VERSION ""

NS_ :

BS_:

BU_: BMU DTI_L DTI_R ECU SBG SHDN C125

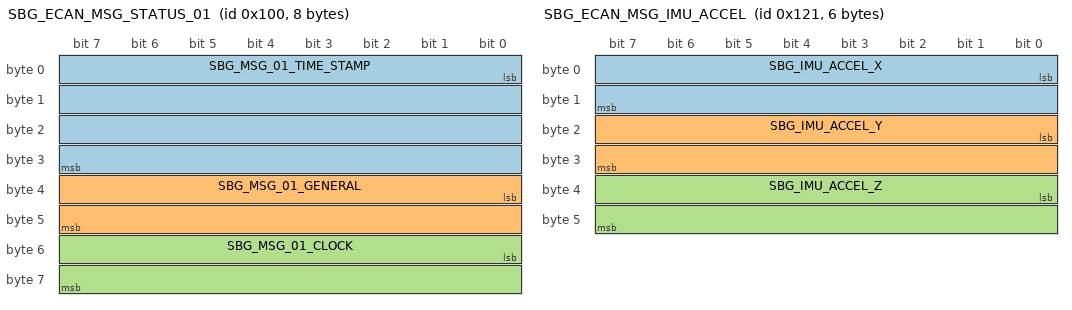
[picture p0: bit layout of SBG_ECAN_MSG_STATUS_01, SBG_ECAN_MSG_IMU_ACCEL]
BO_ 256 SBG_ECAN_MSG_STATUS_01: 8 SBG
 SG_ SBG_MSG_01_TIME_STAMP : 0|32@1+ (1,0) [0|4294970000] "µs" C125
 SG_ SBG_MSG_01_GENERAL : 32|16@1+ (1,0) [0|65535] "" C125
 SG_ SBG_MSG_01_CLOCK : 48|16@1+ (1,0) [0|65535] "" C125

BO_ 289 SBG_ECAN_MSG_IMU_ACCEL: 6 SBG
 SG_ SBG_IMU_ACCEL_X : 0|16@1- (0.01,0) [-327.68|327.67] "m.s-2" C125
 SG_ SBG_IMU_ACCEL_Y : 16|16@1- (0.01,0) [-327.68|327.67] "m.s-2" C125
 SG_ SBG_IMU_ACCEL_Z : 32|16@1- (0.01,0) [-327.68|327.67] "m.s-2" C125

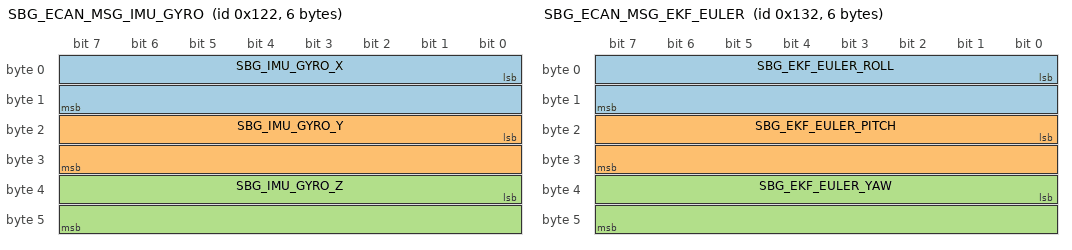
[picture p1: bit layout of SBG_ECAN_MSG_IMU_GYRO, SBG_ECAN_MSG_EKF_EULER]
BO_ 290 SBG_ECAN_MSG_IMU_GYRO: 6 SBG
 SG_ SBG_IMU_GYRO_X : 0|16@1- (0.001,0) [-32.768|32.767] "rad.s-1" C125
 SG_ SBG_IMU_GYRO_Y : 16|16@1- (0.001,0) [-32.768|32.767] "rad.s-1" C125
 SG_ SBG_IMU_GYRO_Z : 32|16@1- (0.001,0) [-32.768|32.767] "rad.s-1" C125

BO_ 304 SBG_ECAN_MSG_EKF_INFO: 4 SBG
 SG_ SBG_EFK_TIME_STAMP : 0|32@1+ (1,0) [0|4294970000] "µs" C125

BO_ 306 SBG_ECAN_MSG_EKF_EULER: 6 SBG
 SG_ SBG_EKF_EULER_ROLL : 0|16@1- (0.0001,0) [-3.2768|3.2767] "rad" C125
 SG_ SBG_EKF_EULER_PITCH : 16|16@1- (0.0001,0) [-3.2768|3.2767] "rad" C125
 SG_ SBG_EKF_EULER_YAW : 32|16@1- (0.0001,0) [-3.2768|3.2767] "rad" C125

BO_ 308 SBG_ECAN_MSG_EKF_POS: 8 SBG
 SG_ SBG_EKF_POS_LATITUDE : 0|32@1- (0.0000001,0) [-214.7483648|214.7483647] "°" C125
 SG_ SBG_EKF_POS_LONGITUDE : 32|32@1- (0.0000001,0) [-214.7483648|214.7483647] "°" C125

BO_ 309 SBG_ECAN_MSG_EKF_ALTITUDE: 6 SBG
 SG_ SBG_EKF_ALTITUDE : 0|32@1- (0.001,0) [-2147480|2147480] "m" C125
 SG_ SBG_EKF_UNDULATION : 32|16@1- (0.005,0) [-163.84|163.835] "m" C125

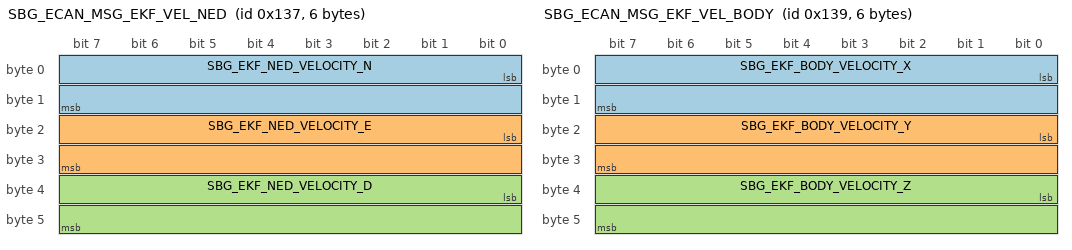
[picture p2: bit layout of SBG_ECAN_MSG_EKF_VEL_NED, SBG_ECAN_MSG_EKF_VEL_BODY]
BO_ 311 SBG_ECAN_MSG_EKF_VEL_NED: 6 SBG
 SG_ SBG_EKF_NED_VELOCITY_N : 0|16@1- (0.01,0) [-327.68|327.67] "m.s-1" C125
 SG_ SBG_EKF_NED_VELOCITY_E : 16|16@1- (0.01,0) [-327.68|327.67] "m.s-1" C125
 SG_ SBG_EKF_NED_VELOCITY_D : 32|16@1- (0.01,0) [-327.68|327.67] "m.s-1" C125

BO_ 313 SBG_ECAN_MSG_EKF_VEL_BODY: 6 SBG
 SG_ SBG_EKF_BODY_VELOCITY_X : 0|16@1- (0.01,0) [-327.68|327.67] "m.s-1" C125
 SG_ SBG_EKF_BODY_VELOCITY_Y : 16|16@1- (0.01,0) [-327.68|327.67] "m.s-1" C125
 SG_ SBG_EKF_BODY_VELOCITY_Z : 32|16@1- (0.01,0) [-327.68|327.67] "m.s-1" C125

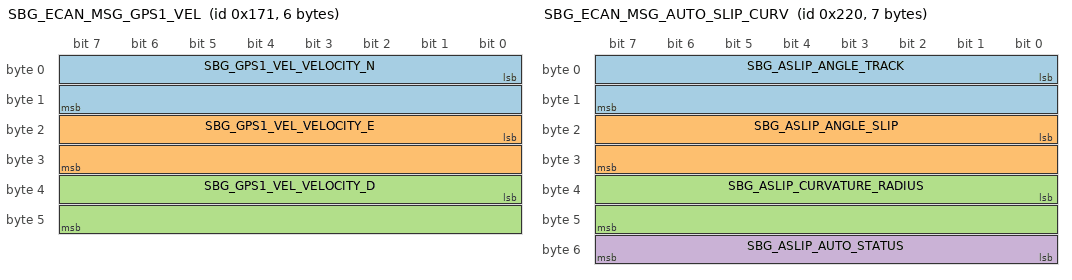
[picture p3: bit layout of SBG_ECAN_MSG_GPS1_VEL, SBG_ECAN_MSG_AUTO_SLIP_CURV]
BO_ 369 SBG_ECAN_MSG_GPS1_VEL: 6 SBG
 SG_ SBG_GPS1_VEL_VELOCITY_N : 0|16@1- (0.01,0) [-327.68|327.67] "m.s-1" C125
 SG_ SBG_GPS1_VEL_VELOCITY_E : 16|16@1- (0.01,0) [-327.68|327.67] "m.s-1" C125
 SG_ SBG_GPS1_VEL_VELOCITY_D : 32|16@1- (0.01,0) [-327.68|327.67] "m.s-1" C125

BO_ 373 SBG_ECAN_MSG_GPS1_POS: 8 SBG
 SG_ SBG_GPS1_POS_LATITUDE : 0|32@1- (0.0000001,0) [-214.7483648|214.7483647] "°" C125
 SG_ SBG_GPS1_POS_LONGITUDE : 32|32@1- (0.0000001,0) [-214.7483648|214.7483647] "°" C125

BO_ 544 SBG_ECAN_MSG_AUTO_SLIP_CURV: 7 SBG
 SG_ SBG_ASLIP_ANGLE_TRACK : 0|16@1- (0.0001,0) [-3.2768|3.2767] "rad" C125
 SG_ SBG_ASLIP_ANGLE_SLIP : 16|16@1- (0.0001,0) [-3.2768|3.2767] "rad" C125
 SG_ SBG_ASLIP_CURVATURE_RADIUS : 32|16@1+ (0.01,0) [0|655.35] "m" C125
 SG_ SBG_ASLIP_AUTO_STATUS : 48|8@1+ (1,0) [0|255] "" C125

BO_ 2147484988 DTI_L_SET_REL_CURRENT: 8 ECU
 SG_ DTI_L_CmdRelCurrent : 7|16@0- (0.1,0) [-100|100] "%" C125

BO_ 2147484989 DTI_R_SET_REL_CURRENT: 8 ECU
 SG_ DTI_R_CmdRelCurrent : 7|16@0- (0.1,0) [-100|100] "%" C125

BO_ 2147486780 DTI_L_DRIVE_ENABLE: 8 ECU
 SG_ DTI_L_CmdDriveEnable : 7|8@0+ (1,0) [0|255] "" C125

BO_ 2147486781 DTI_R_DRIVE_ENABLE: 8 ECU
 SG_ DTI_R_CmdDriveEnable : 7|8@0+ (1,0) [0|255] "" C125

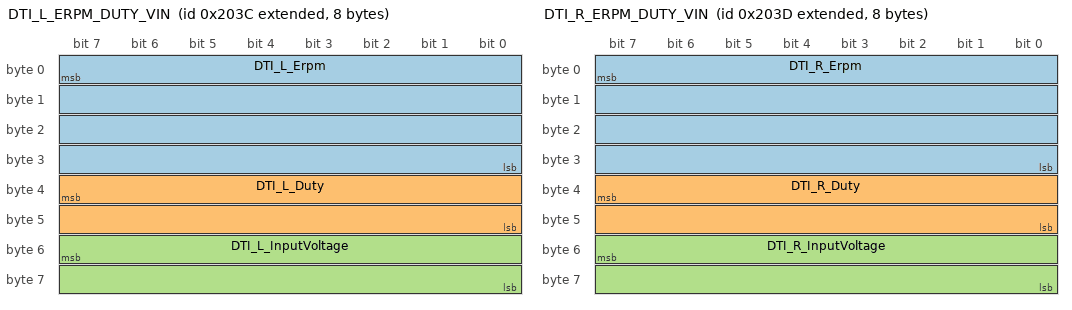
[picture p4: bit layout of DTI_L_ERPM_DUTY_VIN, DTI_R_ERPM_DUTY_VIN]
BO_ 2147491900 DTI_L_ERPM_DUTY_VIN: 8 DTI_L
 SG_ DTI_L_Erpm : 7|32@0- (1,0) [-2147483648|2147483647] "rpm" C125
 SG_ DTI_L_Duty : 39|16@0- (0.1,0) [-3276.8|3276.7] "%" C125
 SG_ DTI_L_InputVoltage : 55|16@0- (1,0) [-32768|32767] "V" C125

BO_ 2147491901 DTI_R_ERPM_DUTY_VIN: 8 DTI_R
 SG_ DTI_R_Erpm : 7|32@0- (1,0) [-2147483648|2147483647] "rpm" C125
 SG_ DTI_R_Duty : 39|16@0- (0.1,0) [-3276.8|3276.7] "%" C125
 SG_ DTI_R_InputVoltage : 55|16@0- (1,0) [-32768|32767] "V" C125

BO_ 2147492156 DTI_L_CURRENTS: 8 DTI_L
 SG_ DTI_L_AcCurrent : 7|16@0- (0.1,0) [-3276.8|3276.7] "A" C125
 SG_ DTI_L_DcCurrent : 23|16@0- (0.1,0) [-3276.8|3276.7] "A" C125

BO_ 2147492157 DTI_R_CURRENTS: 8 DTI_R
 SG_ DTI_R_AcCurrent : 7|16@0- (0.1,0) [-3276.8|3276.7] "A" C125
 SG_ DTI_R_DcCurrent : 23|16@0- (0.1,0) [-3276.8|3276.7] "A" C125

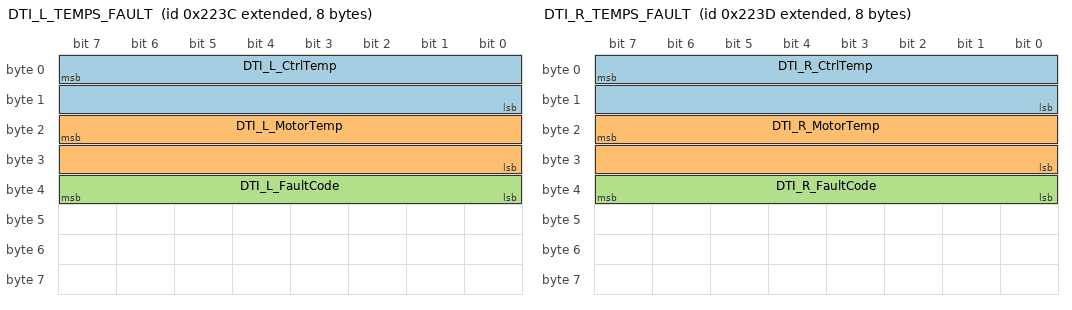
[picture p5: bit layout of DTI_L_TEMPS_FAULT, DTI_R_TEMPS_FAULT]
BO_ 2147492412 DTI_L_TEMPS_FAULT: 8 DTI_L
 SG_ DTI_L_CtrlTemp : 7|16@0- (0.1,0) [-3276.8|3276.7] "degC" C125
 SG_ DTI_L_MotorTemp : 23|16@0- (0.1,0) [-3276.8|3276.7] "degC" C125
 SG_ DTI_L_FaultCode : 39|8@0+ (1,0) [0|255] "" C125

BO_ 2147492413 DTI_R_TEMPS_FAULT: 8 DTI_R
 SG_ DTI_R_CtrlTemp : 7|16@0- (0.1,0) [-3276.8|3276.7] "degC" C125
 SG_ DTI_R_MotorTemp : 23|16@0- (0.1,0) [-3276.8|3276.7] "degC" C125
 SG_ DTI_R_FaultCode : 39|8@0+ (1,0) [0|255] "" C125

BO_ 2147492924 DTI_L_IO_STATUS: 8 DTI_L
 SG_ DTI_L_DriveEnabled : 31|8@0+ (1,0) [0|255] "" C125
 SG_ DTI_L_Limits : 39|16@0+ (1,0) [0|65535] "" C125

BO_ 2147492925 DTI_R_IO_STATUS: 8 DTI_R
 SG_ DTI_R_DriveEnabled : 31|8@0+ (1,0) [0|255] "" C125
 SG_ DTI_R_Limits : 39|16@0+ (1,0) [0|65535] "" C125

BO_ 2281963520 BMU_HEARTBEAT: 8 BMU
 SG_ BMU_State : 0|8@1+ (1,0) [0|255] "" C125
 SG_ BMU_Flags : 8|28@1+ (1,0) [0|268435455] "" C125

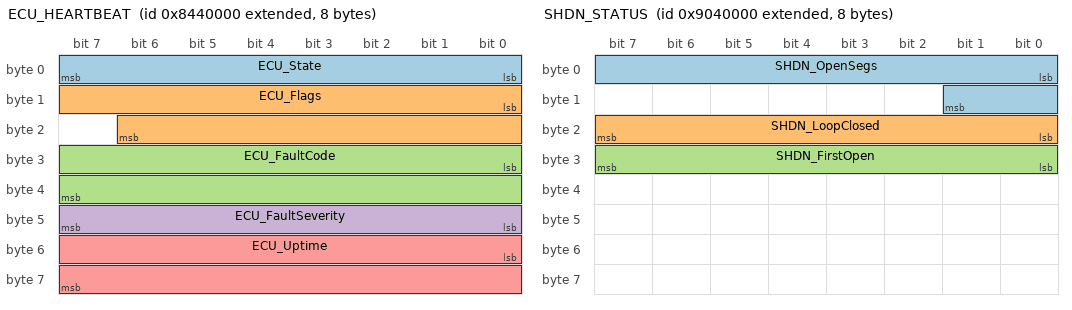
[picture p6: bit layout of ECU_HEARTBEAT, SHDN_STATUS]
BO_ 2286157824 ECU_HEARTBEAT: 8 ECU
 SG_ ECU_State : 0|8@1+ (1,0) [0|255] "" C125
 SG_ ECU_Flags : 8|15@1+ (1,0) [0|32767] "" C125
 SG_ ECU_FaultCode : 24|16@1+ (1,0) [0|65535] "" C125
 SG_ ECU_FaultSeverity : 40|8@1+ (1,0) [0|255] "" C125
 SG_ ECU_Uptime : 48|16@1+ (1,0) [0|65535] "s" C125

BO_ 2298740736 SHDN_STATUS: 8 SHDN
 SG_ SHDN_OpenSegs : 0|10@1+ (1,0) [0|1023] "" C125
 SG_ SHDN_LoopClosed : 16|8@1+ (1,0) [0|255] "" C125
 SG_ SHDN_FirstOpen : 24|8@1+ (1,0) [0|255] "" C125

BO_ 2416446720 BMU_TRANSMIT_PACKINFO: 8 BMU
 SG_ BMU_PackCurrent : 0|32@1- (0.001,0) [-2147483.648|2147483.6469999999] "A" C125
 SG_ BMU_PackVoltage : 32|32@1- (0.001,0) [-2147483.648|2147483.6469999999] "V" C125

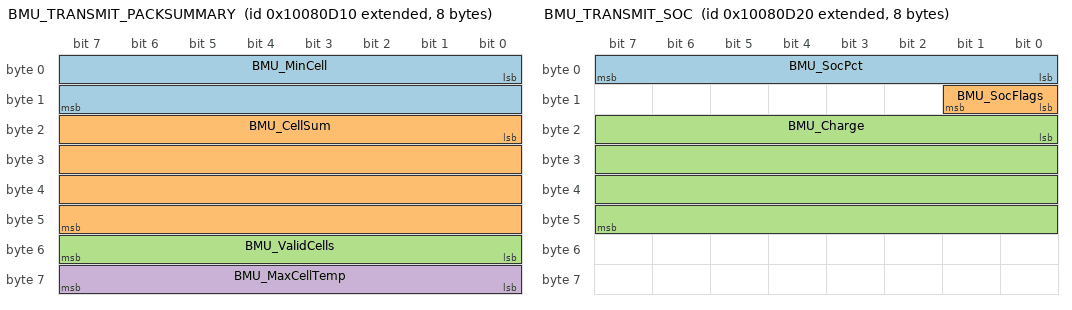
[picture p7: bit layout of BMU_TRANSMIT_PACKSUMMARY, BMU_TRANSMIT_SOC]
BO_ 2416446736 BMU_TRANSMIT_PACKSUMMARY: 8 BMU
 SG_ BMU_MinCell : 0|16@1+ (1,0) [0|65535] "mV" C125
 SG_ BMU_CellSum : 16|32@1+ (1,0) [0|4294967295] "mV" C125
 SG_ BMU_ValidCells : 48|8@1+ (1,0) [0|255] "" C125
 SG_ BMU_MaxCellTemp : 56|8@1+ (1,0) [0|255] "degC" C125

BO_ 2416446752 BMU_TRANSMIT_SOC: 8 BMU
 SG_ BMU_SocPct : 0|8@1+ (1,0) [0|255] "%" C125
 SG_ BMU_SocFlags : 8|2@1+ (1,0) [0|3] "" C125
 SG_ BMU_Charge : 16|32@1- (0.000001,0) [-2147.483648|2147.483647] "Ah" C125

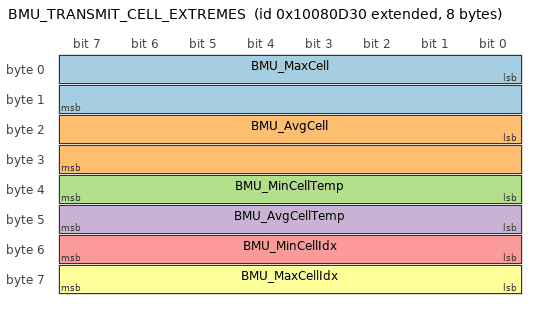
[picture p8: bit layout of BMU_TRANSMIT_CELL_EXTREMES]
BO_ 2416446768 BMU_TRANSMIT_CELL_EXTREMES: 8 BMU
 SG_ BMU_MaxCell : 0|16@1+ (1,0) [0|65535] "mV" C125
 SG_ BMU_AvgCell : 16|16@1+ (1,0) [0|65535] "mV" C125
 SG_ BMU_MinCellTemp : 32|8@1+ (1,0) [0|255] "degC" C125
 SG_ BMU_AvgCellTemp : 40|8@1+ (1,0) [0|255] "degC" C125
 SG_ BMU_MinCellIdx : 48|8@1+ (1,0) [0|255] "" C125
 SG_ BMU_MaxCellIdx : 56|8@1+ (1,0) [0|255] "" C125

CM_ SG_ 2147492924 DTI_L_Limits "b0 DTI_L_LimRpmMin, b1 DTI_L_LimRpmMax, b2 DTI_L_LimPower, b8 DTI_L_LimCapTemp, b9 DTI_L_LimDcCurrent, b10 DTI_L_LimDriveEnable, b11 DTI_L_LimIgbtAccelTemp, b12 DTI_L_LimIgbtTemp, b13 DTI_L_LimInputVoltage, b14 DTI_L_LimMotorAccelTemp, b15 DTI_L_LimMotorTemp";
CM_ SG_ 2147492925 DTI_R_Limits "b0 DTI_R_LimRpmMin, b1 DTI_R_LimRpmMax, b2 DTI_R_LimPower, b8 DTI_R_LimCapTemp, b9 DTI_R_LimDcCurrent, b10 DTI_R_LimDriveEnable, b11 DTI_R_LimIgbtAccelTemp, b12 DTI_R_LimIgbtTemp, b13 DTI_R_LimInputVoltage, b14 DTI_R_LimMotorAccelTemp, b15 DTI_R_LimMotorTemp";
CM_ SG_ 2281963520 BMU_Flags "b0 BMU_F_HbCmu, b1 BMU_F_HbSendyne1, b2 BMU_F_HbSendyne2, b3 BMU_F_HbEcu, b4 BMU_F_HbChrgCtrl, b5 BMU_F_Watchdog, b6 BMU_F_Can1, b7 BMU_F_Can2, b8 BMU_F_ContactorPos, b9 BMU_F_ContactorNeg, b10 BMU_F_ContactorPchrg, b11 BMU_F_PrechargeTimeout, b12 BMU_F_CmuOverVolt, b13 BMU_F_CmuUnderVolt, b14 BMU_F_CmuBadTemp, b15 BMU_F_CmuOpenVolt, b16 BMU_F_CmuOpenTemp, b17 BMU_F_CmuMissingVolt, b18 BMU_F_CmuMissingTemp, b19 BMU_F_ShdnBmu, b20 BMU_F_ShdnPdoc, b21 BMU_F_ShdnImd, b22 BMU_F_ShdnInterlock, b23 BMU_F_Balancing, b24 BMU_F_DieTemps, b25 BMU_F_HvKey, b26 BMU_F_ChrgDetect, b27 BMU_F_ChrgCtrl";
CM_ SG_ 2286157824 ECU_Flags "b0 ECU_F_PedalPolarity, b1 ECU_F_BmuAlive, b2 ECU_F_InvAlive, b3 ECU_F_ShdnClosed, b4 ECU_F_PedalOk, b5 ECU_F_BrakePressed, b6 ECU_F_PrechargeReq, b7 ECU_F_TorqueAllowed, b8 ECU_F_OutputFault, b9 ECU_F_CanAOk, b10 ECU_F_CanBOk, b11 ECU_F_Warning, b12 ECU_F_EepromOk, b13 ECU_F_Calibrated, b14 ECU_F_HvOffReq";
CM_ SG_ 2298740736 SHDN_OpenSegs "b0 SHDN_Seg1Open, b1 SHDN_Seg2Open, b2 SHDN_Seg3Open, b3 SHDN_Seg4Open, b4 SHDN_Seg5Open, b5 SHDN_Seg6Open, b6 SHDN_Seg7Open, b7 SHDN_Seg8Open, b8 SHDN_Seg9Open, b9 SHDN_Seg10Open";
CM_ SG_ 2416446752 BMU_SocFlags "b0 BMU_SocValid, b1 BMU_SocCalibrated";
BA_DEF_  "BusType" STRING ;
BA_DEF_  "DBName" STRING ;
BA_DEF_ BO_  "GenMsgCycleTime" INT 0 65535;
BA_DEF_ BO_  "SendType" STRING;
BA_DEF_ BO_  "MoTeC" STRING;
BA_DEF_ BO_  "Status" STRING;
BA_DEF_ BO_  "VFrameFormat" ENUM "StandardCAN","ExtendedCAN";
BA_DEF_DEF_  "BusType" "CAN";
BA_DEF_DEF_  "DBName" "";
BA_DEF_DEF_  "GenMsgCycleTime" 0;
BA_DEF_DEF_  "SendType" "Cyclic";
BA_DEF_DEF_  "MoTeC" "No";
BA_DEF_DEF_  "Status" "Current";
BA_DEF_DEF_  "VFrameFormat" "StandardCAN";
BA_ "DBName" "qev6_can_a_bmu_qev6_inv_dti_motec";
BA_ "GenMsgCycleTime" BO_ 256 1000;
BA_ "MoTeC" BO_ 256 "Yes";
BA_ "GenMsgCycleTime" BO_ 289 10;
BA_ "MoTeC" BO_ 289 "Yes";
BA_ "GenMsgCycleTime" BO_ 290 10;
BA_ "MoTeC" BO_ 290 "Yes";
BA_ "GenMsgCycleTime" BO_ 304 1000;
BA_ "MoTeC" BO_ 304 "Yes";
BA_ "GenMsgCycleTime" BO_ 306 20;
BA_ "MoTeC" BO_ 306 "Yes";
BA_ "GenMsgCycleTime" BO_ 308 100;
BA_ "MoTeC" BO_ 308 "Yes";
BA_ "GenMsgCycleTime" BO_ 309 100;
BA_ "MoTeC" BO_ 309 "Yes";
BA_ "GenMsgCycleTime" BO_ 311 20;
BA_ "MoTeC" BO_ 311 "Yes";
BA_ "GenMsgCycleTime" BO_ 313 20;
BA_ "MoTeC" BO_ 313 "Yes";
BA_ "GenMsgCycleTime" BO_ 369 100;
BA_ "MoTeC" BO_ 369 "Yes";
BA_ "GenMsgCycleTime" BO_ 373 100;
BA_ "MoTeC" BO_ 373 "Yes";
BA_ "GenMsgCycleTime" BO_ 544 20;
BA_ "MoTeC" BO_ 544 "Yes";
BA_ "GenMsgCycleTime" BO_ 2147484988 10;
BA_ "MoTeC" BO_ 2147484988 "Yes";
BA_ "VFrameFormat" BO_ 2147484988 1;
BA_ "GenMsgCycleTime" BO_ 2147484989 10;
BA_ "MoTeC" BO_ 2147484989 "Yes";
BA_ "VFrameFormat" BO_ 2147484989 1;
BA_ "GenMsgCycleTime" BO_ 2147486780 100;
BA_ "MoTeC" BO_ 2147486780 "Yes";
BA_ "VFrameFormat" BO_ 2147486780 1;
BA_ "GenMsgCycleTime" BO_ 2147486781 100;
BA_ "MoTeC" BO_ 2147486781 "Yes";
BA_ "VFrameFormat" BO_ 2147486781 1;
BA_ "GenMsgCycleTime" BO_ 2147491900 10;
BA_ "MoTeC" BO_ 2147491900 "Yes";
BA_ "VFrameFormat" BO_ 2147491900 1;
BA_ "GenMsgCycleTime" BO_ 2147491901 10;
BA_ "MoTeC" BO_ 2147491901 "Yes";
BA_ "VFrameFormat" BO_ 2147491901 1;
BA_ "GenMsgCycleTime" BO_ 2147492156 10;
BA_ "MoTeC" BO_ 2147492156 "Yes";
BA_ "VFrameFormat" BO_ 2147492156 1;
BA_ "GenMsgCycleTime" BO_ 2147492157 10;
BA_ "MoTeC" BO_ 2147492157 "Yes";
BA_ "VFrameFormat" BO_ 2147492157 1;
BA_ "GenMsgCycleTime" BO_ 2147492412 50;
BA_ "MoTeC" BO_ 2147492412 "Yes";
BA_ "VFrameFormat" BO_ 2147492412 1;
BA_ "GenMsgCycleTime" BO_ 2147492413 50;
BA_ "MoTeC" BO_ 2147492413 "Yes";
BA_ "VFrameFormat" BO_ 2147492413 1;
BA_ "GenMsgCycleTime" BO_ 2147492924 50;
BA_ "MoTeC" BO_ 2147492924 "Yes";
BA_ "VFrameFormat" BO_ 2147492924 1;
BA_ "GenMsgCycleTime" BO_ 2147492925 50;
BA_ "MoTeC" BO_ 2147492925 "Yes";
BA_ "VFrameFormat" BO_ 2147492925 1;
BA_ "GenMsgCycleTime" BO_ 2281963520 100;
BA_ "MoTeC" BO_ 2281963520 "Yes";
BA_ "VFrameFormat" BO_ 2281963520 1;
BA_ "GenMsgCycleTime" BO_ 2286157824 100;
BA_ "MoTeC" BO_ 2286157824 "Yes";
BA_ "VFrameFormat" BO_ 2286157824 1;
BA_ "GenMsgCycleTime" BO_ 2298740736 100;
BA_ "MoTeC" BO_ 2298740736 "Yes";
BA_ "VFrameFormat" BO_ 2298740736 1;
BA_ "GenMsgCycleTime" BO_ 2416446720 100;
BA_ "MoTeC" BO_ 2416446720 "Yes";
BA_ "VFrameFormat" BO_ 2416446720 1;
BA_ "GenMsgCycleTime" BO_ 2416446736 500;
BA_ "MoTeC" BO_ 2416446736 "Yes";
BA_ "VFrameFormat" BO_ 2416446736 1;
BA_ "GenMsgCycleTime" BO_ 2416446752 1000;
BA_ "MoTeC" BO_ 2416446752 "Yes";
BA_ "VFrameFormat" BO_ 2416446752 1;
BA_ "GenMsgCycleTime" BO_ 2416446768 500;
BA_ "MoTeC" BO_ 2416446768 "Yes";
BA_ "VFrameFormat" BO_ 2416446768 1;
VAL_ 2147486780 DTI_L_CmdDriveEnable 0 "NOT_ALLOWED" 1 "ALLOWED" ;
VAL_ 2147486781 DTI_R_CmdDriveEnable 0 "NOT_ALLOWED" 1 "ALLOWED" ;
VAL_ 2147492412 DTI_L_FaultCode 0 "NO_FAULTS" 1 "OVERVOLTAGE" 2 "UNDERVOLTAGE" 3 "DRV" 4 "ABS_OVERCURRENT" 5 "CTLR_OVERTEMP" 6 "MOTOR_OVERTEMP" 7 "SENSOR_WIRE_FAULT" 8 "SENSOR_GENERAL_FAULT" 9 "CAN_COMMAND_ERROR" 10 "ANALOG_INPUT_ERROR" ;
VAL_ 2147492413 DTI_R_FaultCode 0 "NO_FAULTS" 1 "OVERVOLTAGE" 2 "UNDERVOLTAGE" 3 "DRV" 4 "ABS_OVERCURRENT" 5 "CTLR_OVERTEMP" 6 "MOTOR_OVERTEMP" 7 "SENSOR_WIRE_FAULT" 8 "SENSOR_GENERAL_FAULT" 9 "CAN_COMMAND_ERROR" 10 "ANALOG_INPUT_ERROR" ;
VAL_ 2147492924 DTI_L_DriveEnabled 0 "DISABLED" 1 "ENABLED" ;
VAL_ 2147492925 DTI_R_DriveEnabled 0 "DISABLED" 1 "ENABLED" ;
VAL_ 2281963520 BMU_State 0 "START" 1 "INIT_PERIPHERAL" 2 "INIT_CMU" 3 "CHECK_CMU_GPIO" 4 "CHECK_SENDYNE" 5 "CHECK_BOARD" 6 "READY" 7 "PRECHARGE" 8 "TS_ACTIVE" 13 "TRIG_SHDN" 15 "SHUTDOWN" 22 "CHRG_CHECK_BOARD" 23 "CHRG_READY" 24 "CHRG_PRECHARGE" 25 "CHRG_TS_ACTIVE" 26 "CHRG_FAIL" 255 "ERROR" ;
VAL_ 2286157824 ECU_State 0 "BOOT" 1 "POWERUP" 20 "PREFLIGHT" 40 "PRECHARGE" 41 "ENERGISE" 42 "RTD" 100 "DRIVING" 240 "FAULT" 250 "SHUTDOWN" ;
VAL_ 2286157824 ECU_FaultCode 0 "NONE" 257 "BOARD_OUTPUT_INIT" 258 "BOARD_ADC" 259 "BOARD_EEPROM" 260 "BOARD_CAN" 512 "OUTPUT_CRITICAL" 768 "BMU_TIMEOUT" 769 "BMU_SHUTDOWN" 770 "BMU_PRECHARGE_TIMEOUT" 771 "BMU_HV_FAULT" 772 "BMU_TEMP_FAULT" 773 "BMU_ISOLATION" 774 "BMU_CONTACTOR" 775 "BMU_STATE_UNEXPECTED" 1024 "INV_FAULT" 1040 "INV_TIMEOUT" 1056 "INV_ENERGISE_TIMEOUT" 1057 "INV_ENABLE_FAIL" 1280 "PEDAL_APPS" 1281 "PEDAL_BSE" 1282 "PEDAL_BRAKE_APPS" 1283 "PEDAL_UNCALIBRATED" 1536 "SAFETY_SHDN_OPEN" 1537 "SAFETY_SHDN_TIMEOUT" 1538 "SAFETY_WATCHDOG" 2048 "COMM_CAN_A_BUSOFF" 2049 "COMM_CAN_B_BUSOFF" ;
VAL_ 2286157824 ECU_FaultSeverity 0 "NONE" 1 "WARNING" 2 "CRITICAL" 3 "FATAL" ;
VAL_ 2298740736 SHDN_LoopClosed 0 "OPEN" 1 "CLOSED" ;
VAL_ 2298740736 SHDN_FirstOpen 0 "NONE" ;
